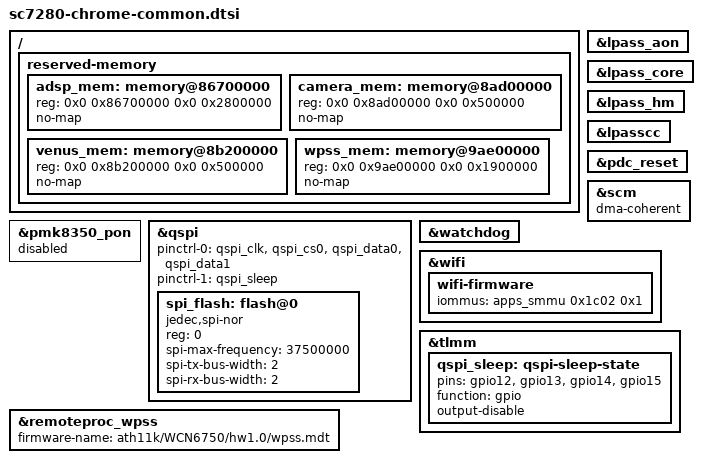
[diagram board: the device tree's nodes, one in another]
/delete-node/ &hyp_mem;
/delete-node/ &xbl_mem;
/delete-node/ &reserved_xbl_uefi_log;
/delete-node/ &sec_apps_mem;
/ {
	reserved-memory {
		adsp_mem: memory@86700000 {
			reg = <0x0 0x86700000 0x0 0x2800000>;
			no-map;
		};
		camera_mem: memory@8ad00000 {
			reg = <0x0 0x8ad00000 0x0 0x500000>;
			no-map;
		};
		venus_mem: memory@8b200000 {
			reg = <0x0 0x8b200000 0x0 0x500000>;
			no-map;
		};
		wpss_mem: memory@9ae00000 {
			reg = <0x0 0x9ae00000 0x0 0x1900000>;
			no-map;
		};
	};
};
&lpass_aon {
	status = "okay";
};
&lpass_core {
	status = "okay";
};
&lpass_hm {
	status = "okay";
};
&lpasscc {
	status = "okay";
};
&pdc_reset {
	status = "okay";
};
&pmk8350_pon {
	status = "disabled";
};
&qspi {
	status = "okay";
	pinctrl-names = "default", "sleep";
	pinctrl-0 = <&qspi_clk>, <&qspi_cs0>, <&qspi_data0>, <&qspi_data1>;
	pinctrl-1 = <&qspi_sleep>;
	spi_flash: flash@0 {
		compatible = "jedec,spi-nor";
		reg = <0>;
		spi-max-frequency = <37500000>;
		spi-tx-bus-width = <2>;
		spi-rx-bus-width = <2>;
	};
};
&remoteproc_wpss {
	status = "okay";
	firmware-name = "ath11k/WCN6750/hw1.0/wpss.mdt";
};
&scm {
	dma-coherent;
};
&watchdog {
	status = "okay";
};
&wifi {
	status = "okay";
	wifi-firmware {
		iommus = <&apps_smmu 0x1c02 0x1>;
	};
};
&tlmm {
	qspi_sleep: qspi-sleep-state {
		pins = "gpio12", "gpio13", "gpio14", "gpio15";
		function = "gpio";
		output-disable;
	};
};
